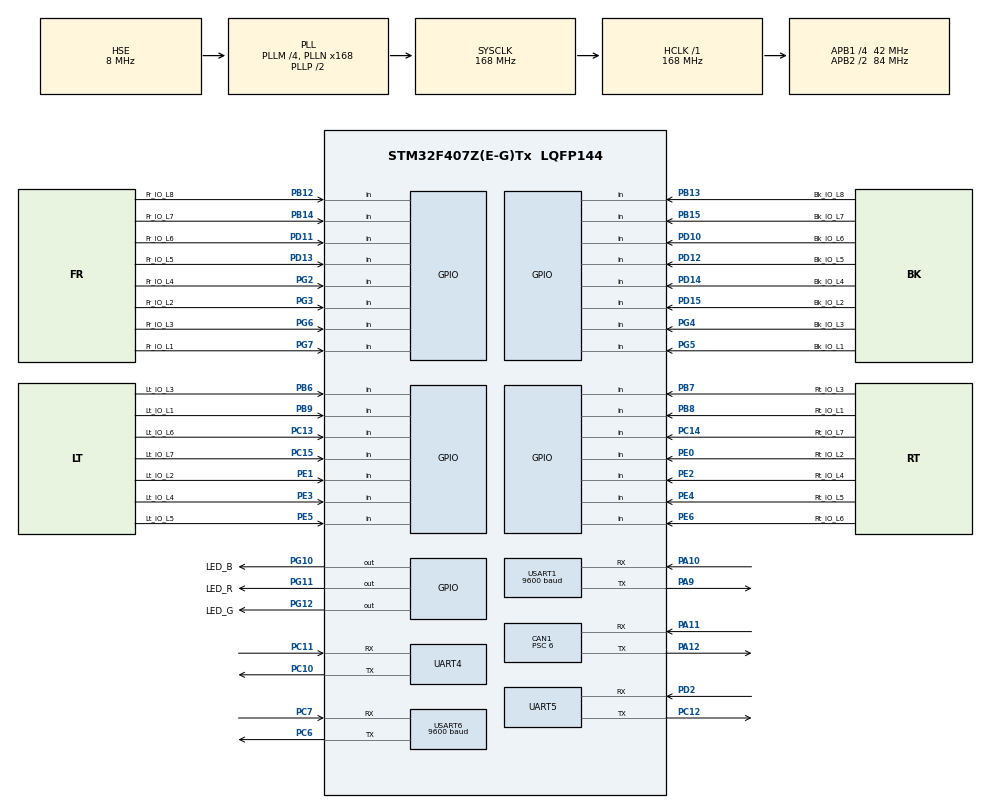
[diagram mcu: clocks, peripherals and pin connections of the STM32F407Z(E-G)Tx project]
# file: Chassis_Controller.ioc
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CAN1.ABOM=ENABLE
CAN1.AWUM=ENABLE
CAN1.BS1=CAN_BS1_3TQ
CAN1.BS2=CAN_BS2_3TQ
CAN1.CalculateBaudRate=1000000
CAN1.CalculateTimeBit=1000
CAN1.CalculateTimeQuantum=142.85714285714286
CAN1.Prescaler=6
FREERTOS.Tasks01=Chassis_Move,24,512,Chassis_Run,As weak,NULL,Dynamic,NULL,NULL;Line_Update,25,256,Line_Refresh,As weak,NULL,Dynamic,NULL,NULL;Arm_Move_Basic,24,128,Arm_Move_Base,As weak,NULL,Dynamic,NULL,NULL;Arm_Move_Contro,24,256,Arm_Move_Ctrl,As weak,NULL,Dynamic,NULL,NULL
Mcu.Family=STM32F4
Mcu.Name=STM32F407Z(E-G)Tx
Mcu.Package=LQFP144
NVIC.CAN1_RX0_IRQn=true\:5\:0\:false\:false\:true\:true\:true\:true\:true
NVIC.CAN1_SCE_IRQn=true\:5\:0\:false\:false\:true\:true\:true\:true\:true
NVIC.PriorityGroup=NVIC_PRIORITYGROUP_4
NVIC.TIM8_TRG_COM_TIM14_IRQn=true\:15\:0\:false\:false\:true\:false\:false\:true\:true
NVIC.TimeBase=TIM8_TRG_COM_TIM14_IRQn
NVIC.TimeBaseIP=TIM14
NVIC.UART4_IRQn=true\:5\:0\:false\:false\:true\:true\:true\:true\:true
NVIC.USART1_IRQn=true\:5\:0\:false\:false\:true\:true\:true\:true\:true
NVIC.USART6_IRQn=true\:5\:0\:false\:false\:true\:true\:true\:true\:true
PA10.GPIO_PuPd=GPIO_PULLUP
PA10.Mode=Asynchronous
PA10.Signal=USART1_RX
PA11.GPIO_PuPd=GPIO_PULLUP
PA11.Mode=CAN_Activate
PA11.Signal=CAN1_RX
PA12.GPIO_PuPd=GPIO_PULLUP
PA12.Mode=CAN_Activate
PA12.Signal=CAN1_TX
PA13.Mode=Serial_Wire
PA13.Signal=SYS_JTMS-SWDIO
PA14.Mode=Serial_Wire
PA14.Signal=SYS_JTCK-SWCLK
PA9.GPIO_PuPd=GPIO_PULLUP
PA9.Mode=Asynchronous
PA9.Signal=USART1_TX
PB12.GPIO_Label=Fr_IO_L8
PB12.GPIO_PuPd=GPIO_PULLUP
PB12.Signal=GPIO_Input
PB13.GPIO_Label=Bk_IO_L8
PB13.GPIO_PuPd=GPIO_PULLUP
PB13.Signal=GPIO_Input
PB14.GPIO_Label=Fr_IO_L7
PB14.GPIO_PuPd=GPIO_PULLUP
PB14.Signal=GPIO_Input
PB15.GPIO_Label=Bk_IO_L7
PB15.GPIO_PuPd=GPIO_PULLUP
PB15.Signal=GPIO_Input
PB6.GPIO_Label=Lt_IO_L3
PB6.GPIO_PuPd=GPIO_PULLUP
PB6.Signal=GPIO_Input
PB7.GPIO_Label=Rt_IO_L3
PB7.GPIO_PuPd=GPIO_PULLUP
PB7.Signal=GPIO_Input
PB8.GPIO_Label=Rt_IO_L1
PB8.GPIO_PuPd=GPIO_PULLUP
PB8.Signal=GPIO_Input
PB9.GPIO_Label=Lt_IO_L1
PB9.GPIO_PuPd=GPIO_PULLUP
PB9.Signal=GPIO_Input
PC10.GPIO_PuPd=GPIO_PULLUP
PC10.Mode=Asynchronous
PC10.Signal=UART4_TX
PC11.GPIO_PuPd=GPIO_PULLUP
PC11.Mode=Asynchronous
PC11.Signal=UART4_RX
PC12.GPIO_PuPd=GPIO_PULLUP
PC12.Mode=Asynchronous
PC12.Signal=UART5_TX
PC13-ANTI_TAMP.GPIO_Label=Lt_IO_L6
PC13-ANTI_TAMP.GPIO_PuPd=GPIO_PULLUP
PC13-ANTI_TAMP.Signal=GPIO_Input
PC14-OSC32_IN.GPIO_Label=Rt_IO_L7
PC14-OSC32_IN.GPIO_PuPd=GPIO_PULLUP
PC14-OSC32_IN.Signal=GPIO_Input
PC15-OSC32_OUT.GPIO_Label=Lt_IO_L7
PC15-OSC32_OUT.GPIO_PuPd=GPIO_PULLUP
PC15-OSC32_OUT.Signal=GPIO_Input
PC6.GPIO_PuPd=GPIO_PULLUP
PC6.Mode=Asynchronous
PC6.Signal=USART6_TX
PC7.GPIO_PuPd=GPIO_PULLUP
PC7.Mode=Asynchronous
PC7.Signal=USART6_RX
PD10.GPIO_Label=Bk_IO_L6
PD10.GPIO_PuPd=GPIO_PULLUP
PD10.Signal=GPIO_Input
PD11.GPIO_Label=Fr_IO_L6
PD11.GPIO_PuPd=GPIO_PULLUP
PD11.Signal=GPIO_Input
PD12.GPIO_Label=Bk_IO_L5
PD12.GPIO_PuPd=GPIO_PULLUP
PD12.Signal=GPIO_Input
PD13.GPIO_Label=Fr_IO_L5
PD13.GPIO_PuPd=GPIO_PULLUP
PD13.Signal=GPIO_Input
PD14.GPIO_Label=Bk_IO_L4
PD14.GPIO_PuPd=GPIO_PULLUP
PD14.Signal=GPIO_Input
PD15.GPIO_Label=Bk_IO_L2
PD15.GPIO_PuPd=GPIO_PULLUP
PD15.Signal=GPIO_Input
PD2.GPIO_PuPd=GPIO_PULLUP
PD2.Mode=Asynchronous
PD2.Signal=UART5_RX
PE0.GPIO_Label=Rt_IO_L2
PE0.GPIO_PuPd=GPIO_PULLUP
PE0.Signal=GPIO_Input
PE1.GPIO_Label=Lt_IO_L2
PE1.GPIO_PuPd=GPIO_PULLUP
PE1.Signal=GPIO_Input
PE2.GPIO_Label=Rt_IO_L4
PE2.GPIO_PuPd=GPIO_PULLUP
PE2.Signal=GPIO_Input
PE3.GPIO_Label=Lt_IO_L4
PE3.GPIO_PuPd=GPIO_PULLUP
PE3.Signal=GPIO_Input
PE4.GPIO_Label=Rt_IO_L5
PE4.GPIO_PuPd=GPIO_PULLUP
PE4.Signal=GPIO_Input
PE5.GPIO_Label=Lt_IO_L5
PE5.GPIO_PuPd=GPIO_PULLUP
PE5.Signal=GPIO_Input
PE6.GPIO_Label=Rt_IO_L6
PE6.GPIO_PuPd=GPIO_PULLUP
PE6.Signal=GPIO_Input
PG10.GPIO_Label=LED_B
PG10.Signal=GPIO_Output
PG11.GPIO_Label=LED_R
PG11.Signal=GPIO_Output
PG12.GPIO_Label=LED_G
PG12.Signal=GPIO_Output
PG2.GPIO_Label=Fr_IO_L4
PG2.GPIO_PuPd=GPIO_PULLUP
PG2.Signal=GPIO_Input
PG3.GPIO_Label=Fr_IO_L2
PG3.GPIO_PuPd=GPIO_PULLUP
PG3.Signal=GPIO_Input
PG4.GPIO_Label=Bk_IO_L3
PG4.GPIO_PuPd=GPIO_PULLUP
PG4.Signal=GPIO_Input
PG5.GPIO_Label=Bk_IO_L1
PG5.GPIO_PuPd=GPIO_PULLUP
PG5.Signal=GPIO_Input
PG6.GPIO_Label=Fr_IO_L3
PG6.GPIO_PuPd=GPIO_PULLUP
PG6.Signal=GPIO_Input
PG7.GPIO_Label=Fr_IO_L1
PG7.GPIO_PuPd=GPIO_PULLUP
PG7.Signal=GPIO_Input
PH0-OSC_IN.Mode=HSE-External-Oscillator
PH0-OSC_IN.Signal=RCC_OSC_IN
PH1-OSC_OUT.Mode=HSE-External-Oscillator
PH1-OSC_OUT.Signal=RCC_OSC_OUT
ProjectManager.HeapSize=0x200
ProjectManager.StackSize=0x400
ProjectManager.TargetToolchain=MDK-ARM V5.32
RCC.48MHZClocksFreq_Value=84000000
RCC.AHBFreq_Value=168000000
RCC.APB1CLKDivider=RCC_HCLK_DIV4
RCC.APB1Freq_Value=42000000
RCC.APB1TimFreq_Value=84000000
RCC.APB2CLKDivider=RCC_HCLK_DIV2
RCC.APB2Freq_Value=84000000
RCC.APB2TimFreq_Value=168000000
RCC.CortexFreq_Value=168000000
RCC.HCLKFreq_Value=168000000
RCC.HSE_VALUE=8000000
RCC.HSI_VALUE=16000000
RCC.LSE_VALUE=32768
RCC.PLLM=4
RCC.PLLN=168
RCC.PLLSourceVirtual=RCC_PLLSOURCE_HSE
RCC.SYSCLKFreq_VALUE=168000000
RCC.SYSCLKSource=RCC_SYSCLKSOURCE_PLLCLK
RCC.VCOOutputFreq_Value=336000000
UART4.VirtualMode=Asynchronous
UART5.VirtualMode=Asynchronous
USART1.BaudRate=9600
USART1.VirtualMode=VM_ASYNC
USART6.BaudRate=9600
USART6.VirtualMode=VM_ASYNC
VP_FREERTOS_VS_CMSIS_V2.Mode=CMSIS_V2
VP_SYS_VS_tim14.Mode=TIM14
board=custom

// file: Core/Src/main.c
/* USER CODE BEGIN Header */
/**
  ******************************************************************************
  * @file           : main.c
  * @brief          : Main program body
  ******************************************************************************
  * @attention
  *
  * Copyright (c) 2022 STMicroelectronics.
  * All rights reserved.
  *
  * This software is licensed under terms that can be found in the LICENSE file
  * in the root directory of this software component.
  * If no LICENSE file comes with this software, it is provided AS-IS.
  *
  ******************************************************************************
  */
/* USER CODE END Header */
#include "main.h"
#include "cmsis_os.h"
#include "can.h"
#include "usart.h"
#include "gpio.h"

/* USER CODE BEGIN Includes */
#include "my_task.h"
/* USER CODE END Includes */

void SystemClock_Config(void);
void MX_FREERTOS_Init(void);

int main(void)
{

  /* MCU Configuration--------------------------------------------------------*/

  /* Reset of all peripherals, Initializes the Flash interface and the Systick. */
  HAL_Init();

  /* Configure the system clock */
  SystemClock_Config();

  /* Initialize all configured peripherals */
  MX_GPIO_Init();
  MX_CAN1_Init();
  MX_USART1_UART_Init();
  MX_USART6_UART_Init();
  MX_UART5_Init();
  MX_UART4_Init();
  /* USER CODE BEGIN 2 */

	Program_Init();
//	HAL_GPIO_WritePin(LED_B_GPIO_Port,LED_B_Pin,GPIO_PIN_SET);
//	HAL_GPIO_WritePin(LED_G_GPIO_Port,LED_G_Pin,GPIO_PIN_SET);
//	HAL_GPIO_WritePin(LED_R_GPIO_Port,LED_R_Pin,GPIO_PIN_RESET);
  /* USER CODE END 2 */

  /* Init scheduler */
  osKernelInitialize();  /* Call init function for freertos objects (in freertos.c) */
  MX_FREERTOS_Init();

  /* Start scheduler */
  osKernelStart();

  /* We should never get here as control is now taken by the scheduler */
  /* Infinite loop */
  while (1)
  {

  }
}

void SystemClock_Config(void)
{
  RCC_OscInitTypeDef RCC_OscInitStruct = {0};
  RCC_ClkInitTypeDef RCC_ClkInitStruct = {0};

  /** Configure the main internal regulator output voltage
  */
  __HAL_RCC_PWR_CLK_ENABLE();
  __HAL_PWR_VOLTAGESCALING_CONFIG(PWR_REGULATOR_VOLTAGE_SCALE1);

  /** Initializes the RCC Oscillators according to the specified parameters
  * in the RCC_OscInitTypeDef structure.
  */
  RCC_OscInitStruct.OscillatorType = RCC_OSCILLATORTYPE_HSE;
  RCC_OscInitStruct.HSEState = RCC_HSE_ON;
  RCC_OscInitStruct.PLL.PLLState = RCC_PLL_ON;
  RCC_OscInitStruct.PLL.PLLSource = RCC_PLLSOURCE_HSE;
  RCC_OscInitStruct.PLL.PLLM = 4;
  RCC_OscInitStruct.PLL.PLLN = 168;
  RCC_OscInitStruct.PLL.PLLP = RCC_PLLP_DIV2;
  RCC_OscInitStruct.PLL.PLLQ = 4;
  if (HAL_RCC_OscConfig(&RCC_OscInitStruct) != HAL_OK)
  {
    Error_Handler();
  }

  /** Initializes the CPU, AHB and APB buses clocks
  */
  RCC_ClkInitStruct.ClockType = RCC_CLOCKTYPE_HCLK|RCC_CLOCKTYPE_SYSCLK
                              |RCC_CLOCKTYPE_PCLK1|RCC_CLOCKTYPE_PCLK2;
  RCC_ClkInitStruct.SYSCLKSource = RCC_SYSCLKSOURCE_PLLCLK;
  RCC_ClkInitStruct.AHBCLKDivider = RCC_SYSCLK_DIV1;
  RCC_ClkInitStruct.APB1CLKDivider = RCC_HCLK_DIV4;
  RCC_ClkInitStruct.APB2CLKDivider = RCC_HCLK_DIV2;

  if (HAL_RCC_ClockConfig(&RCC_ClkInitStruct, FLASH_LATENCY_5) != HAL_OK)
  {
    Error_Handler();
  }
}

void HAL_TIM_PeriodElapsedCallback(TIM_HandleTypeDef *htim)
{
  if (htim->Instance == TIM14) {
    HAL_IncTick();
  }
}

void Error_Handler(void)
{
  __disable_irq();
  while (1)
  {
  }
}

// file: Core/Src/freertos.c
/* USER CODE BEGIN Header */
/**
  ******************************************************************************
  * File Name          : freertos.c
  * Description        : Code for freertos applications
  ******************************************************************************
  * @attention
  *
  * Copyright (c) 2022 STMicroelectronics.
  * All rights reserved.
  *
  * This software is licensed under terms that can be found in the LICENSE file
  * in the root directory of this software component.
  * If no LICENSE file comes with this software, it is provided AS-IS.
  *
  ******************************************************************************
  */
/* USER CODE END Header */

#include "FreeRTOS.h"
#include "task.h"
#include "main.h"
#include "cmsis_os.h"

/* Definitions for Chassis_Move */
osThreadId_t Chassis_MoveHandle;
const osThreadAttr_t Chassis_Move_attributes = {
  .name = "Chassis_Move",
  .stack_size = 512 * 4,
  .priority = (osPriority_t) osPriorityNormal,
};
/* Definitions for Line_Update */
osThreadId_t Line_UpdateHandle;
const osThreadAttr_t Line_Update_attributes = {
  .name = "Line_Update",
  .stack_size = 256 * 4,
  .priority = (osPriority_t) osPriorityNormal1,
};
/* Definitions for Arm_Move_Basic */
osThreadId_t Arm_Move_BasicHandle;
const osThreadAttr_t Arm_Move_Basic_attributes = {
  .name = "Arm_Move_Basic",
  .stack_size = 128 * 4,
  .priority = (osPriority_t) osPriorityNormal,
};
/* Definitions for Arm_Move_Contro */
osThreadId_t Arm_Move_ControHandle;
const osThreadAttr_t Arm_Move_Contro_attributes = {
  .name = "Arm_Move_Contro",
  .stack_size = 256 * 4,
  .priority = (osPriority_t) osPriorityNormal,
};

void Chassis_Run(void *argument);
void Line_Refresh(void *argument);
void Arm_Move_Base(void *argument);
void Arm_Move_Ctrl(void *argument);

void MX_FREERTOS_Init(void); /* (MISRA C 2004 rule 8.1) */

void MX_FREERTOS_Init(void) {

  /* Create the thread(s) */
  /* creation of Chassis_Move */
  Chassis_MoveHandle = osThreadNew(Chassis_Run, NULL, &Chassis_Move_attributes);

  /* creation of Line_Update */
  Line_UpdateHandle = osThreadNew(Line_Refresh, NULL, &Line_Update_attributes);

  /* creation of Arm_Move_Basic */
  Arm_Move_BasicHandle = osThreadNew(Arm_Move_Base, NULL, &Arm_Move_Basic_attributes);

  /* creation of Arm_Move_Contro */
  Arm_Move_ControHandle = osThreadNew(Arm_Move_Ctrl, NULL, &Arm_Move_Contro_attributes);

}

__weak void Chassis_Run(void *argument)
{
  for(;;)
  {
    osDelay(1);
  }
}

__weak void Line_Refresh(void *argument)
{
  for(;;)
  {
    osDelay(1);
  }
}

__weak void Arm_Move_Base(void *argument)
{
  for(;;)
  {
    osDelay(1);
  }
}

__weak void Arm_Move_Ctrl(void *argument)
{
  for(;;)
  {
    osDelay(1);
  }
}
